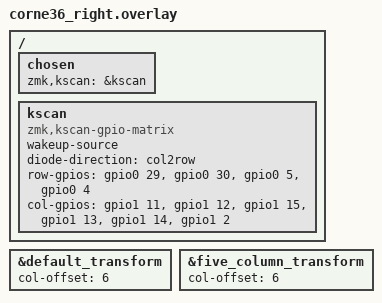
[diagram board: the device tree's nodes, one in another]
/*
 * Copyright (c) 2020 Pete Johanson
 *
 * SPDX-License-Identifier: MIT
 */

#include "corne36.dtsi"
/ {
    chosen {
        zmk,kscan = &kscan;
    };
    kscan: kscan {
        compatible = "zmk,kscan-gpio-matrix";
        wakeup-source;

        diode-direction = "col2row";
        
        row-gpios
            = <&gpio0 29 (GPIO_ACTIVE_HIGH | GPIO_PULL_DOWN)>
			, <&gpio0 30 (GPIO_ACTIVE_HIGH | GPIO_PULL_DOWN)>
			, <&gpio0 5 (GPIO_ACTIVE_HIGH | GPIO_PULL_DOWN)>
			, <&gpio0 4 (GPIO_ACTIVE_HIGH | GPIO_PULL_DOWN)>
			;
        col-gpios
            = <&gpio1 11 GPIO_ACTIVE_HIGH>
            , <&gpio1 12 GPIO_ACTIVE_HIGH>
            , <&gpio1 15 GPIO_ACTIVE_HIGH>
            , <&gpio1 13 GPIO_ACTIVE_HIGH>
            , <&gpio1 14 GPIO_ACTIVE_HIGH>
            , <&gpio1 2 GPIO_ACTIVE_HIGH>
            ;
    };
};
&default_transform {
    col-offset = <6>;
};

&five_column_transform {
    col-offset = <6>;
};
